# N32F030 register map
File version: 1.0
Registers are 32-bit, read-write, reset 0x0 unless marked. A register's access mark holds for its fields unless they carry their own. Offsets are from the block's base; [hi:lo] are bit positions; 'fields as' and 'values as' point back to an identical list.

## BPWM — BPWM Register Map
Base 0x40140000
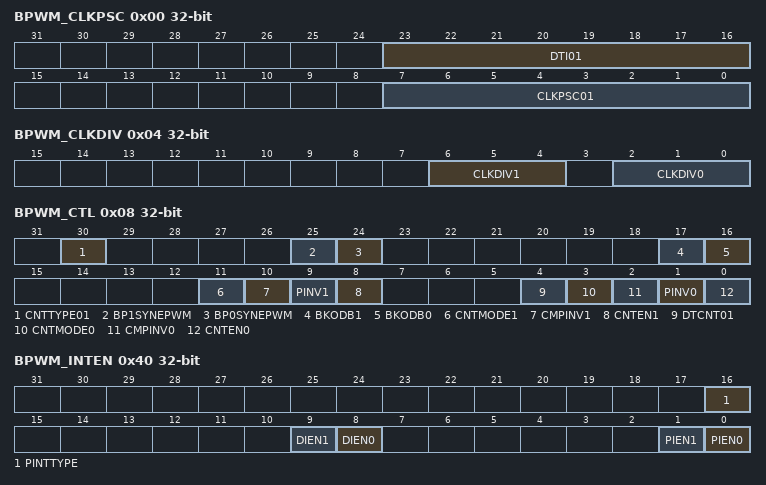
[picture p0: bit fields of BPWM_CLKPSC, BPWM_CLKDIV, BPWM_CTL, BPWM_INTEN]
0x00 BPWM_CLKPSC — Basic PWM Pre-scalar Register
  [23:16] DTI01 — Dead-zone Interval for Pair of Channel 0 and Channel 1. These 8-bit determine the Dead-zone length.
  [7:0] CLKPSC01 — Clock Prescaler. Clock input is divided by (CLKPSC01 + 1) before it is fed to the corresponding PWM-timer
0x04 BPWM_CLKDIV — Basic PWM Clock Source Divider Select Register
  [6:4] CLKDIV1 — PWM Timer 1 Clock Source Divider Selection. Select clock source divider for PWM timer 1.
    0=1/2; 1=1/4; 2=1/8; 3=1/16; 4=1
  [2:0] CLKDIV0 — PWM Timer 0 Clock Source Divider Selection. Select clock source divider for PWM timer 0. (Table is the same as CLKDIV1)
0x08 BPWM_CTL — Basic PWM Control Register
  [30] CNTTYPE01 — PWM01 Aligned Type Selection
    0=Edge-aligned type; 1=Center-aligned type
  [25] BP1SYNEPWM
    1=When EPWM enable will also enable BPWM1 at the same time
  [24] BP0SYNEPWM
    1=When EPWM enable will also enable BPWM0 at the same time
  [17] BKODB1 — BPWM Channel 1 Brake Output Selection. Note: This bit effects BPWM1 only when BP1SYNEPWM is set
    0=BPWM1 output low when fault brake conditions asserted; 1=BPWM1 output high when fault brake conditions asserted
  [16] BKODB0 — BPWM Channel 1 Brake Output Selection. Note: This bit effects BPWM0 only when BP0SYNEPWM is set
    0=BPWM0 output low when fault brake conditions asserted; 1=BPWM0 output high when fault brake conditions asserted
  [11] CNTMODE1 — PWM-timer 1 Auto-reload/One-shot Mode. Note: If there is a transition at this bit, it will cause BPWM_PERIOD1 and BPWM_CMPDAT1 be cleared.
    0=One-shot mode; 1=Auto-reload mode
  [10] CMPINV1 — PWM-timer 1 Output Inverter Enable Control
    0=Inverter Disabled; 1=Inverter Enabled
  [9] PINV1 — PWM-timer 1 Output Polar Inverse Enable Control
    0=PWM1 output polar inverse Disabled; 1=PWM1 output polar inverse Enabled
  [8] CNTEN1 — PWM-timer 1 Enable Control
    0=Corresponding PWM-Timer Stopped; 1=Corresponding PWM-Timer Start Running
  [4] DTCNT01 — Dead-zone 0 Generator Enable Control. Note: When Dead-zone generator is enabled, the pair of PWM0 and PWM1 becomes a complementary pair.
    0=Dead-zone 0 Generator Disabled; 1=Dead-zone 0 Generator Enabled
  [3] CNTMODE0 — PWM-timer 0 Auto-reload/One-shot Mode. Note: If there is a transition at this bit, it will cause BPWM_PERIOD0 and BPWM_CMPDAT0 be cleared.
    0=One-shot mode; 1=Auto-reload mode
  [2] CMPINV0 — PWM-timer 0 Output Inverter Enable Control
    0=Inverter Disabled; 1=Inverter Enabled
  [1] PINV0 — PWM-timer 0 Output Polar Inverse Enable Control
    0=PWM0 output polar inverse Disabled; 1=PWM0 output polar inverse Enabled
  [0] CNTEN0 — PWM-timer 0 Enable Control
    0=The corresponding PWM-Timer stops running; 1=The corresponding PWM-Timer starts running
0x0C BPWM_PERIOD0 — Basic PWM Period Counter Register 0
  [15:0] PERIOD — Basic PWM Period Counter Register. PERIOD data determines the PWM period. For Edge-aligned type: Note: Any write to PERIOD will take effect in next PWM cycle. Note: When PWM operating at Center-aligned type, PERIOD value should be set between 0x0000 to 0xFFFE. If PERIOD equal to 0xFFFF, the PWM will work unpredictable. Note: When PERIOD value is set to 0, PWM output is always high.
0x10 BPWM_CMPDAT0 — Basic PWM Comparator Register 0
  [15:0] CMP — PWM Comparator Register. CMP determines the PWM duty. Note: Any write to PERIOD will take effect in next PWM cycle.
0x14 BPWM_CNT0 ro — Basic PWM Data Register 0
  [15:0] CNT — PWM Data Register. User can monitor CNT to know the current value in 16-bit counter.
0x18 BPWM_PERIOD1 — Basic PWM Period Counter Register 1
  fields as BPWM_PERIOD0
0x1C BPWM_CMPDAT1 — Basic PWM Comparator Register 1
  fields as BPWM_CMPDAT0
0x20 BPWM_CNT1 ro — Basic PWM Data Register 1
  fields as BPWM_CNT0
0x40 BPWM_INTEN — Basic PWM Interrupt Enable Register
  [16] PINTTYPE — BPWM Interrupt Period Type Selection. Note: This bit is effective when BPWM in Center-aligned type only.
    0=PIFn will be set if BPWM counter underflow; 1=PIFn will be set if BPWM counter matches PERIODn register
  [9] DIEN1 — BPWM Channel 1 Duty Interrupt Enable Control
    0=BPWM Channel 1 Duty Interrupt Disabled; 1=BPWM Channel 1 Duty Interrupt Enabled
  [8] DIEN0 — BPWM Channel 0 Duty Interrupt Enable Control
    0=BPWM Channel 0 Duty Interrupt Disabled; 1=BPWM Channel 0 Duty Interrupt Enabled
  [1] PIEN1 — BPWM Channel 1 Period Interrupt Enable Control
    0=BPWM Channel 1 Period Interrupt Disabled; 1=BPWM Channel 1 Period Interrupt Enabled
  [0] PIEN0 — BPWM Channel 0 Period Interrupt Enable Control
    0=BPWM Channel 0 Period Interrupt Disabled; 1=BPWM Channel 0 Period Interrupt Enabled
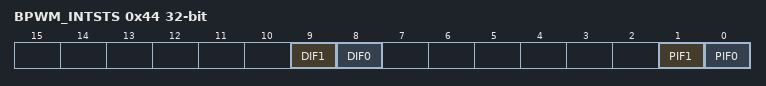
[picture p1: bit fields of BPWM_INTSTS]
0x44 BPWM_INTSTS — Basic PWM Interrupt Indication Register
  [9] DIF1 — BPWM Channel 1 Duty Interrupt Flag. Flag is set by hardware when channel 1 BPWM counter down count and reaches BPWM_CMPDAT 1, software can clear this bit by writing a one to it. Note: If CMP equal to PERIOD, this flag is not working in Edge-aligned type selection
  [8] DIF0 — BPWM Channel 0 Duty Interrupt Flag. Flag is set by hardware when channel 0 BPWM counter down count and reaches BPWM_CMPDAT 0, software can clear this bit by writing a one to it. Note: If CMP equal to PERIOD, this flag is not working in Edge-aligned type selection
  [1] PIF1 — BPWM Channel 1 Period Interrupt Status. This bit is set by hardware when BPWM1 counter reaches the requirement of interrupt (depend on PINTTYPE bit of PWM_INTEN register), software can write 1 to clear this bit to 0.
  [0] PIF0 — BPWM Channel 0 Period Interrupt Status. This bit is set by hardware when BPWM0 counter reaches the requirement of interrupt (depend on PINTTYPE bit of PWM_INTEN register), software can write 1 to clear this bit to 0.
